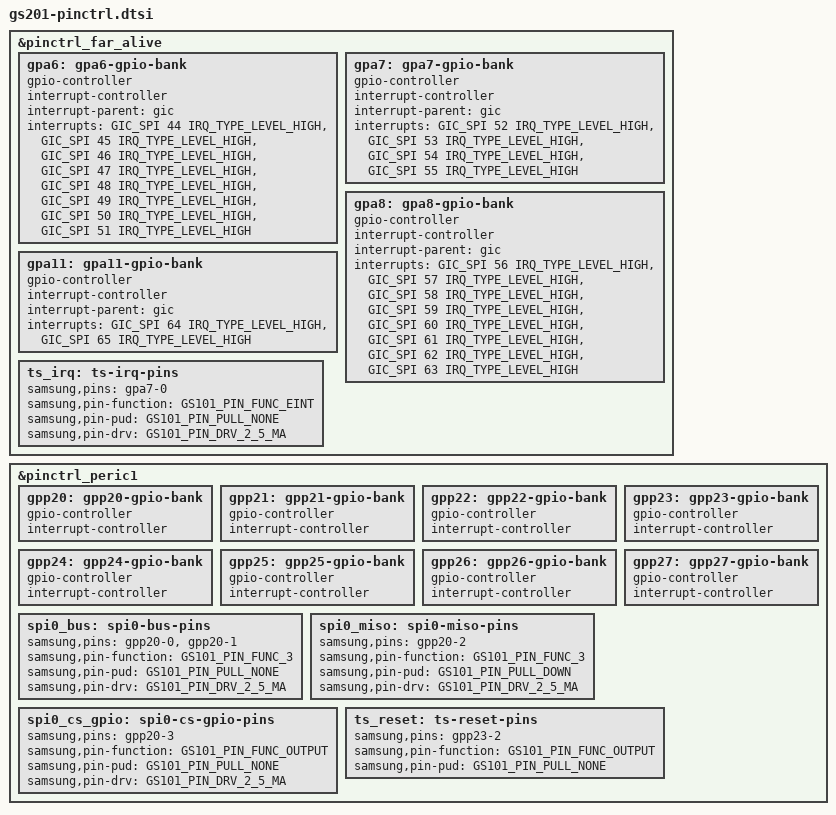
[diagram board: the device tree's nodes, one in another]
// SPDX-License-Identifier: GPL-2.0-only
/*
 * Google GS201 (Tensor G2) SoC pin-mux and pin-config device tree source
 *
 * Bank layout and wake-up interrupt numbers from Google's GPL gs201 device
 * tree. Note that the ALIVE wake-up interrupts skip EINT19, so from EINT20
 * on the GIC number is the EINT number minus one.
 */

#include "gs101-pinctrl.h"

&pinctrl_far_alive {
	gpa6: gpa6-gpio-bank {
		gpio-controller;
		#gpio-cells = <2>;
		interrupt-controller;
		#interrupt-cells = <2>;
		interrupt-parent = <&gic>;
		interrupts = <GIC_SPI 44 IRQ_TYPE_LEVEL_HIGH>,
			     <GIC_SPI 45 IRQ_TYPE_LEVEL_HIGH>,
			     <GIC_SPI 46 IRQ_TYPE_LEVEL_HIGH>,
			     <GIC_SPI 47 IRQ_TYPE_LEVEL_HIGH>,
			     <GIC_SPI 48 IRQ_TYPE_LEVEL_HIGH>,
			     <GIC_SPI 49 IRQ_TYPE_LEVEL_HIGH>,
			     <GIC_SPI 50 IRQ_TYPE_LEVEL_HIGH>,
			     <GIC_SPI 51 IRQ_TYPE_LEVEL_HIGH>;
	};

	gpa7: gpa7-gpio-bank {
		gpio-controller;
		#gpio-cells = <2>;
		interrupt-controller;
		#interrupt-cells = <2>;
		interrupt-parent = <&gic>;
		interrupts = <GIC_SPI 52 IRQ_TYPE_LEVEL_HIGH>,
			     <GIC_SPI 53 IRQ_TYPE_LEVEL_HIGH>,
			     <GIC_SPI 54 IRQ_TYPE_LEVEL_HIGH>,
			     <GIC_SPI 55 IRQ_TYPE_LEVEL_HIGH>;
	};

	gpa8: gpa8-gpio-bank {
		gpio-controller;
		#gpio-cells = <2>;
		interrupt-controller;
		#interrupt-cells = <2>;
		interrupt-parent = <&gic>;
		interrupts = <GIC_SPI 56 IRQ_TYPE_LEVEL_HIGH>,
			     <GIC_SPI 57 IRQ_TYPE_LEVEL_HIGH>,
			     <GIC_SPI 58 IRQ_TYPE_LEVEL_HIGH>,
			     <GIC_SPI 59 IRQ_TYPE_LEVEL_HIGH>,
			     <GIC_SPI 60 IRQ_TYPE_LEVEL_HIGH>,
			     <GIC_SPI 61 IRQ_TYPE_LEVEL_HIGH>,
			     <GIC_SPI 62 IRQ_TYPE_LEVEL_HIGH>,
			     <GIC_SPI 63 IRQ_TYPE_LEVEL_HIGH>;
	};

	gpa11: gpa11-gpio-bank {
		gpio-controller;
		#gpio-cells = <2>;
		interrupt-controller;
		#interrupt-cells = <2>;
		interrupt-parent = <&gic>;
		interrupts = <GIC_SPI 64 IRQ_TYPE_LEVEL_HIGH>,
			     <GIC_SPI 65 IRQ_TYPE_LEVEL_HIGH>;
	};

	ts_irq: ts-irq-pins {
		samsung,pins = "gpa7-0";
		samsung,pin-function = <GS101_PIN_FUNC_EINT>;
		samsung,pin-pud = <GS101_PIN_PULL_NONE>;
		samsung,pin-drv = <GS101_PIN_DRV_2_5_MA>;
	};
};

&pinctrl_peric1 {
	gpp20: gpp20-gpio-bank {
		gpio-controller;
		#gpio-cells = <2>;
		interrupt-controller;
		#interrupt-cells = <2>;
	};

	gpp21: gpp21-gpio-bank {
		gpio-controller;
		#gpio-cells = <2>;
		interrupt-controller;
		#interrupt-cells = <2>;
	};

	gpp22: gpp22-gpio-bank {
		gpio-controller;
		#gpio-cells = <2>;
		interrupt-controller;
		#interrupt-cells = <2>;
	};

	gpp23: gpp23-gpio-bank {
		gpio-controller;
		#gpio-cells = <2>;
		interrupt-controller;
		#interrupt-cells = <2>;
	};

	gpp24: gpp24-gpio-bank {
		gpio-controller;
		#gpio-cells = <2>;
		interrupt-controller;
		#interrupt-cells = <2>;
	};

	gpp25: gpp25-gpio-bank {
		gpio-controller;
		#gpio-cells = <2>;
		interrupt-controller;
		#interrupt-cells = <2>;
	};

	gpp26: gpp26-gpio-bank {
		gpio-controller;
		#gpio-cells = <2>;
		interrupt-controller;
		#interrupt-cells = <2>;
	};

	gpp27: gpp27-gpio-bank {
		gpio-controller;
		#gpio-cells = <2>;
		interrupt-controller;
		#interrupt-cells = <2>;
	};

	spi0_bus: spi0-bus-pins {
		samsung,pins = "gpp20-0", "gpp20-1";
		samsung,pin-function = <GS101_PIN_FUNC_3>;
		samsung,pin-pud = <GS101_PIN_PULL_NONE>;
		samsung,pin-drv = <GS101_PIN_DRV_2_5_MA>;
	};

	spi0_miso: spi0-miso-pins {
		samsung,pins = "gpp20-2";
		samsung,pin-function = <GS101_PIN_FUNC_3>;
		samsung,pin-pud = <GS101_PIN_PULL_DOWN>;
		samsung,pin-drv = <GS101_PIN_DRV_2_5_MA>;
	};

	spi0_cs_gpio: spi0-cs-gpio-pins {
		samsung,pins = "gpp20-3";
		samsung,pin-function = <GS101_PIN_FUNC_OUTPUT>;
		samsung,pin-pud = <GS101_PIN_PULL_NONE>;
		samsung,pin-drv = <GS101_PIN_DRV_2_5_MA>;
	};

	ts_reset: ts-reset-pins {
		samsung,pins = "gpp23-2";
		samsung,pin-function = <GS101_PIN_FUNC_OUTPUT>;
		samsung,pin-pud = <GS101_PIN_PULL_NONE>;
	};
};
